# earlgrey register map
Vendor: lowRISC; File version: 0.1
CPU: ibex rev01, little endian, no MPU, no FPU, VTOR, 2 interrupt priority bits, 2 interrupts
Registers are 32-bit, read-write, no defined reset value unless marked. A register's access mark holds for its fields unless they carry their own. Offsets are from the block's base; [hi:lo] are bit positions; {n}, {i} and the like mark numbered series; 'fields as' and 'values as' point back to an identical list.

## KEYMGR — Managing identities and root keys; shielding confidential assets from software; providing a key derivation interface for software
Base 0x41140000
0x40 CFG_REGWEN ro — Key manager configuration enable
  [0] EN — key manager configuration enable.When key manager operation is started (see CONTROL), registers protected by this EN are no longermodifiable until the operation completes.
0x44 START — Key manager operation start
  [0] EN — Start key manager operations
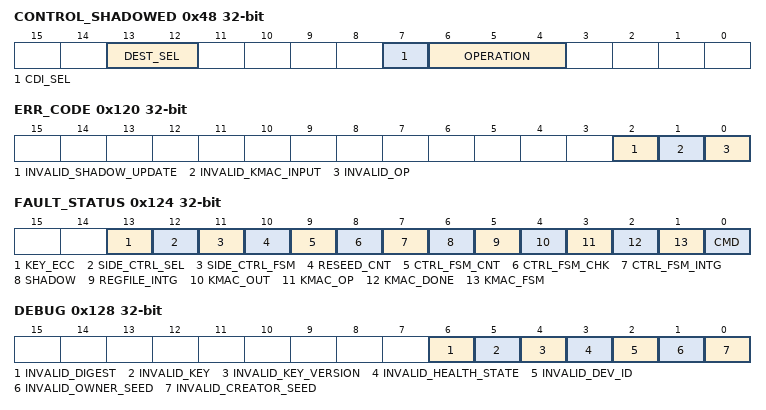
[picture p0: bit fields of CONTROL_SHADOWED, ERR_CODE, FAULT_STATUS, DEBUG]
0x48 CONTROL_SHADOWED — Key manager operation controls
  [13:12] DEST_SEL — When the OPERATION field is programmed to generate output, this field selectsthe appropriate crypto cipher target.This field should be programmed for both hw / sw generation, as this helps diverisifies the output.
  [7] CDI_SEL — When the OPERATION field is programmed to generate output, this field selectsthe appropriate CDI to use.This field should be programmed for both hw / sw generation.
  [6:4] OPERATION — Key manager operation selection. All values not enumerated below behave the same as disable
0x4C SIDELOAD_CLEAR — sideload key slots clear
  [2:0] VAL — Depending on the value programmed, a different sideload key slot is cleared.If the value programmed is not one of the enumerated values below, ALL sideloadkey slots are continuously cleared. In order to stop continuous clearing, SW shouldtoggle the clear bit again (i.e. disable continuous clearing).
0x50 RESEED_INTERVAL_REGWEN — regwen for reseed interval
  [0] EN — Configuration enable for reseed interval
0x54 RESEED_INTERVAL_SHADOWED — Reseed interval for key manager entropy reseed
  [15:0] VAL — Number of key manager cycles before the entropy is reseeded
0x58 SW_BINDING_REGWEN — Register write enable for SOFTWARE_BINDING
  [0] EN — Software binding register write enable.This is locked by software and unlocked by hardware upon a successful advance call.Software binding resets to 1, and its value cannot be altered by software until advancement to Init state.
{0x5C+4i} SEALING_SW_BINDING_{i} (i=0..7) — Software binding input to sealing portion of the key manager.This register is lockable and shared between key manager stages.This binding value is not considered secret, however its integrity is very important.The software binding is locked by software and unlocked by hardware upon a successful advance operation.
  [31:0] VAL_{i} — Software binding value
{0x7C+4i} ATTEST_SW_BINDING_{i} (i=0..7) — Software binding input to the attestation portion of the key manager.This register is lockable and shared between key manager stages.This binding value is not considered secret, however its integrity is very important.The software binding is locked by software and unlocked by hardware upon a successful advance operation.
  [31:0] VAL_{i} — Software binding value
{0x9C+4i} Salt_{i} (i=0..7) — Salt value used as part of output generation
  [31:0] VAL_{i} — Salt value
0xBC KEY_VERSION — Version used as part of output generation
  [31:0] VAL_0 — Key version
0xC0 MAX_CREATOR_KEY_VER_REGWEN — Register write enable for MAX_CREATOR_KEY_VERSION
  [0] EN — MAX_CREATOR_KEY_VERSION configure enable.
0xC4 MAX_CREATOR_KEY_VER_SHADOWED — Max creator key version
  [31:0] VAL — Max key version.Any key version up to the value specificed in this register is valid.
0xC8 MAX_OWNER_INT_KEY_VER_REGWEN — Register write enable for MAX_OWNER_INT_KEY_VERSION
  [0] EN — MAX_OWNER_INTERMEDIATE_KEY configure enable.
0xCC MAX_OWNER_INT_KEY_VER_SHADOWED — Max owner intermediate key version
  fields as MAX_CREATOR_KEY_VER_SHADOWED
0xD0 MAX_OWNER_KEY_VER_REGWEN — Register write enable for MAX_OWNER_KEY_VERSION
  [0] EN — MAX_OWNER_KEY configure enable.
0xD4 MAX_OWNER_KEY_VER_SHADOWED — Max owner key version
  fields as MAX_CREATOR_KEY_VER_SHADOWED
{0xD8+4i} SW_SHARE0_OUTPUT_{i} ro (i=0..7) — Key manager software output.When a software output operation is selected, the results of the operation are placedhere.
  [31:0] VAL_{i} — Software output value
{0xF8+4i} SW_SHARE1_OUTPUT_{i} ro (i=0..7) — Key manager software output.When a software output operation is selected, the results of the operation are placedhere.
  [31:0] VAL_{i} — Software output value
0x118 WORKING_STATE ro — Key manager working state.This is a readout of the current key manager working state
  [2:0] STATE — Key manager control state
0x11C OP_STATUS — Key manager status.Hardware sets the status based on software initiated operations.This register must be explicitly cleared by software.Software clears by writing back whatever it reads.
  [1:0] STATUS — Operation status.
0x120 ERR_CODE — Key manager error code.This register must be explicitly cleared by software.This register represents both synchronous and asynchronous recoverableerrors.Synchronous errors refer to those that only happen when a keymgr operation isinvoked, while asynchronous refers to errors that can happen at any time.
  [2] INVALID_SHADOW_UPDATE — An error observed during shadow register updates, asynchronous error
  [1] INVALID_KMAC_INPUT — Invalid data issued to kmac interface, synchronous error
  [0] INVALID_OP — Invalid operation issued to key manager, synchronous error
0x124 FAULT_STATUS ro — This register represents both synchronous and asynchronous fatal faults.Synchronous faults refer to those that only happen when a keymgr operation isinvoked, while asynchronous refers to faults that can happen at any time.
  [13] KEY_ECC — Secret key ecc error, asynchronous fault
  [12] SIDE_CTRL_SEL — Sideload control key select error, synchronous fault
  [11] SIDE_CTRL_FSM — Sideload control FSM integrity error, asynchronous fault
  [10] RESEED_CNT — Reseed counter integrity error, asynchronous fault
  [9] CTRL_FSM_CNT — Control FSM counter integrity error, asynchronous fault
  [8] CTRL_FSM_CHK — Control FSM cross check error, asynchronous fault
  [7] CTRL_FSM_INTG — Control FSM integrity error, asynchronous fault
  [6] SHADOW — Shadow copy storage error, asynchronous fault
  [5] REGFILE_INTG — Register file integrity error, asynchronous fault
  [4] KMAC_OUT — KMAC data returned as all 0's or all 1's - synchronous fault
  [3] KMAC_OP — KMAC reported an error during keymgr usage, this should never happen - synchronous fault.
  [2] KMAC_DONE — The kmac transfer interface encountered an unexpected done, asynchronous fault.
  [1] KMAC_FSM — The kmac transfer interface FSM is in an invalid state, asynchronous fault.
  [0] CMD — A non-onehot command was seen in kmac, asynchronous fault.
0x128 DEBUG — The register holds some debug information that may be convenient if keymgrmisbehaves.
  [6] INVALID_DIGEST — ROM digest failed input checks during operation
  [5] INVALID_KEY — Key fed to kmac failed input checks during operation
  [4] INVALID_KEY_VERSION — Key version failed input checks during operation
  [3] INVALID_HEALTH_STATE — Health state failed input checks during operation
  [2] INVALID_DEV_ID — Device ID failed input checks during operation
  [1] INVALID_OWNER_SEED — Owner seed failed input checks during operation
  [0] INVALID_CREATOR_SEED — Creator seed failed input checks during operation
